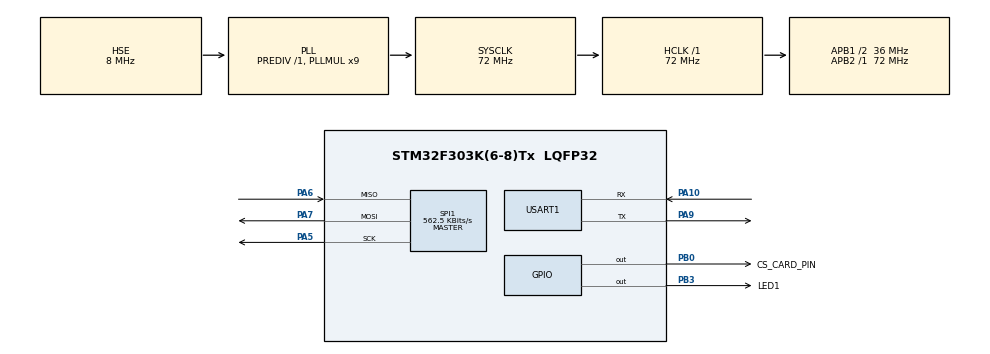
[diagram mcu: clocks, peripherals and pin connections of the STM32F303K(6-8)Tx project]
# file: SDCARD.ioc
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FATFS._MAX_SS=4096
FATFS._USE_LFN=1
Mcu.Family=STM32F3
Mcu.Name=STM32F303K(6-8)Tx
Mcu.Package=LQFP32
NVIC.PriorityGroup=NVIC_PRIORITYGROUP_4
PA10.Mode=Asynchronous
PA10.Signal=USART1_RX
PA13.Mode=Serial_Wire
PA13.Signal=SYS_JTMS-SWDIO
PA14.Mode=Serial_Wire
PA14.Signal=SYS_JTCK-SWCLK
PA5.Mode=Full_Duplex_Master
PA5.Signal=SPI1_SCK
PA6.Mode=Full_Duplex_Master
PA6.Signal=SPI1_MISO
PA7.Mode=Full_Duplex_Master
PA7.Signal=SPI1_MOSI
PA9.Mode=Asynchronous
PA9.Signal=USART1_TX
PB0.GPIO_Label=CS_CARD_PIN
PB0.Signal=GPIO_Output
PB3.GPIO_Label=LED1
PB3.Signal=GPIO_Output
PF0\ /\ OSC_IN.Mode=HSE-External-Oscillator
PF0\ /\ OSC_IN.Signal=RCC_OSC_IN
PF1\ /\ OSC_OUT.Mode=HSE-External-Oscillator
PF1\ /\ OSC_OUT.Signal=RCC_OSC_OUT
ProjectManager.HeapSize=0x200
ProjectManager.StackSize=0x400
ProjectManager.TargetToolchain=STM32CubeIDE
RCC.AHBFreq_Value=72000000
RCC.APB1CLKDivider=RCC_HCLK_DIV2
RCC.APB1Freq_Value=36000000
RCC.APB1TimFreq_Value=72000000
RCC.APB2Freq_Value=72000000
RCC.APB2TimFreq_Value=72000000
RCC.CortexFreq_Value=72000000
RCC.HCLKFreq_Value=72000000
RCC.HSE_VALUE=8000000
RCC.HSI_VALUE=8000000
RCC.PLLMUL=RCC_PLL_MUL9
RCC.PLLSourceVirtual=RCC_PLLSOURCE_HSE
RCC.SYSCLKFreq_VALUE=72000000
RCC.SYSCLKSourceVirtual=RCC_SYSCLKSOURCE_PLLCLK
SPI1.BaudRatePrescaler=SPI_BAUDRATEPRESCALER_128
SPI1.CalculateBaudRate=562.5 KBits/s
SPI1.Direction=SPI_DIRECTION_2LINES
SPI1.Mode=SPI_MODE_MASTER
SPI1.VirtualType=VM_MASTER
USART1.VirtualMode-Asynchronous=VM_ASYNC
VP_FATFS_VS_Generic.Mode=User_defined
board=custom

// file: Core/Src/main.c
/* USER CODE BEGIN Header */
/**
  ******************************************************************************
  * @file           : main.c
  * @brief          : Main program body
  ******************************************************************************
  * @attention
  *
  * <h2><center>&copy; Copyright (c) 2020 STMicroelectronics.
  * All rights reserved.</center></h2>
  *
  * This software component is licensed by ST under BSD 3-Clause license,
  * the "License"; You may not use this file except in compliance with the
  * License. You may obtain a copy of the License at:
  *                        opensource.org/licenses/BSD-3-Clause
  *
  ******************************************************************************
  */
/* USER CODE END Header */
#include "main.h"
#include "fatfs.h"

/* USER CODE BEGIN Includes */
#include <stdio.h>
#include <string.h>
#include <stdarg.h> //for va_list var arg functions

/* USER CODE END Includes */

SPI_HandleTypeDef hspi1;

UART_HandleTypeDef huart1;

void SystemClock_Config(void);
static void MX_GPIO_Init(void);
static void MX_SPI1_Init(void);
static void MX_USART1_UART_Init(void);
/* USER CODE BEGIN PFP */
void myprintf(const char *fmt, ...);
/* USER CODE END PFP */

/* USER CODE BEGIN 0 */
void myprintf(const char *fmt, ...) {
  static char buffer[256];
  va_list args;
  va_start(args, fmt);
  vsnprintf(buffer, sizeof(buffer), fmt, args);
  va_end(args);

  int len = strlen(buffer);
  HAL_UART_Transmit(&huart1, (uint8_t*)buffer, len, -1);
}
/* USER CODE END 0 */

int main(void)
{

  /* MCU Configuration--------------------------------------------------------*/

  /* Reset of all peripherals, Initializes the Flash interface and the Systick. */
  HAL_Init();

  /* Configure the system clock */
  SystemClock_Config();

  /* Initialize all configured peripherals */
  MX_GPIO_Init();
  MX_SPI1_Init();
  MX_USART1_UART_Init();
  MX_FATFS_Init();

  /* Infinite loop */
    while (1)
    {

    /* USER CODE BEGIN 3 */
        //Blink the LED every second
  	  HAL_GPIO_TogglePin(LED1_GPIO_Port, LED1_Pin);
  	  HAL_Delay(1000);
    }
  /* USER CODE END 3 */
}

void SystemClock_Config(void)
{
  RCC_OscInitTypeDef RCC_OscInitStruct = {0};
  RCC_ClkInitTypeDef RCC_ClkInitStruct = {0};
  RCC_PeriphCLKInitTypeDef PeriphClkInit = {0};

  /** Initializes the RCC Oscillators according to the specified parameters
  * in the RCC_OscInitTypeDef structure.
  */
  RCC_OscInitStruct.OscillatorType = RCC_OSCILLATORTYPE_HSE;
  RCC_OscInitStruct.HSEState = RCC_HSE_ON;
  RCC_OscInitStruct.HSEPredivValue = RCC_HSE_PREDIV_DIV1;
  RCC_OscInitStruct.HSIState = RCC_HSI_ON;
  RCC_OscInitStruct.PLL.PLLState = RCC_PLL_ON;
  RCC_OscInitStruct.PLL.PLLSource = RCC_PLLSOURCE_HSE;
  RCC_OscInitStruct.PLL.PLLMUL = RCC_PLL_MUL9;
  if (HAL_RCC_OscConfig(&RCC_OscInitStruct) != HAL_OK)
  {
    Error_Handler();
  }
  /** Initializes the CPU, AHB and APB buses clocks
  */
  RCC_ClkInitStruct.ClockType = RCC_CLOCKTYPE_HCLK|RCC_CLOCKTYPE_SYSCLK
                              |RCC_CLOCKTYPE_PCLK1|RCC_CLOCKTYPE_PCLK2;
  RCC_ClkInitStruct.SYSCLKSource = RCC_SYSCLKSOURCE_PLLCLK;
  RCC_ClkInitStruct.AHBCLKDivider = RCC_SYSCLK_DIV1;
  RCC_ClkInitStruct.APB1CLKDivider = RCC_HCLK_DIV2;
  RCC_ClkInitStruct.APB2CLKDivider = RCC_HCLK_DIV1;

  if (HAL_RCC_ClockConfig(&RCC_ClkInitStruct, FLASH_LATENCY_2) != HAL_OK)
  {
    Error_Handler();
  }
  PeriphClkInit.PeriphClockSelection = RCC_PERIPHCLK_USART1;
  PeriphClkInit.Usart1ClockSelection = RCC_USART1CLKSOURCE_PCLK1;
  if (HAL_RCCEx_PeriphCLKConfig(&PeriphClkInit) != HAL_OK)
  {
    Error_Handler();
  }
}

static void MX_SPI1_Init(void)
{

  /* SPI1 parameter configuration*/
  hspi1.Instance = SPI1;
  hspi1.Init.Mode = SPI_MODE_MASTER;
  hspi1.Init.Direction = SPI_DIRECTION_2LINES;
  hspi1.Init.DataSize = SPI_DATASIZE_4BIT;
  hspi1.Init.CLKPolarity = SPI_POLARITY_LOW;
  hspi1.Init.CLKPhase = SPI_PHASE_1EDGE;
  hspi1.Init.NSS = SPI_NSS_SOFT;
  hspi1.Init.BaudRatePrescaler = SPI_BAUDRATEPRESCALER_128;
  hspi1.Init.FirstBit = SPI_FIRSTBIT_MSB;
  hspi1.Init.TIMode = SPI_TIMODE_DISABLE;
  hspi1.Init.CRCCalculation = SPI_CRCCALCULATION_DISABLE;
  hspi1.Init.CRCPolynomial = 7;
  hspi1.Init.CRCLength = SPI_CRC_LENGTH_DATASIZE;
  hspi1.Init.NSSPMode = SPI_NSS_PULSE_ENABLE;
  if (HAL_SPI_Init(&hspi1) != HAL_OK)
  {
    Error_Handler();
  }

}

static void MX_USART1_UART_Init(void)
{

  huart1.Instance = USART1;
  huart1.Init.BaudRate = 38400;
  huart1.Init.WordLength = UART_WORDLENGTH_8B;
  huart1.Init.StopBits = UART_STOPBITS_1;
  huart1.Init.Parity = UART_PARITY_NONE;
  huart1.Init.Mode = UART_MODE_TX_RX;
  huart1.Init.HwFlowCtl = UART_HWCONTROL_NONE;
  huart1.Init.OverSampling = UART_OVERSAMPLING_16;
  huart1.Init.OneBitSampling = UART_ONE_BIT_SAMPLE_DISABLE;
  huart1.AdvancedInit.AdvFeatureInit = UART_ADVFEATURE_NO_INIT;
  if (HAL_UART_Init(&huart1) != HAL_OK)
  {
    Error_Handler();
  }

}

static void MX_GPIO_Init(void)
{
  GPIO_InitTypeDef GPIO_InitStruct = {0};

  /* GPIO Ports Clock Enable */
  __HAL_RCC_GPIOF_CLK_ENABLE();
  __HAL_RCC_GPIOA_CLK_ENABLE();
  __HAL_RCC_GPIOB_CLK_ENABLE();

  /*Configure GPIO pin Output Level */
  HAL_GPIO_WritePin(GPIOB, CS_CARD_PIN_Pin|LED1_Pin, GPIO_PIN_RESET);

  /*Configure GPIO pins : CS_CARD_PIN_Pin LED1_Pin */
  GPIO_InitStruct.Pin = CS_CARD_PIN_Pin|LED1_Pin;
  GPIO_InitStruct.Mode = GPIO_MODE_OUTPUT_PP;
  GPIO_InitStruct.Pull = GPIO_NOPULL;
  GPIO_InitStruct.Speed = GPIO_SPEED_FREQ_LOW;
  HAL_GPIO_Init(GPIOB, &GPIO_InitStruct);

}

void Error_Handler(void)
{
}

/************************ (C) COPYRIGHT STMicroelectronics *****END OF FILE****/
